AUTOSAR XML (schema 4-0-3)
standard types defined: Boolean, UInt16, UInt32, UInt8
package /AUTOSAR_Platform/DataConstrs
  range DC_Boolean: raw 0..1
  range DC_UInt16: raw 0..65535
  range DC_UInt8: raw 0..255
package /PATAC/MSM/ComponentTypes
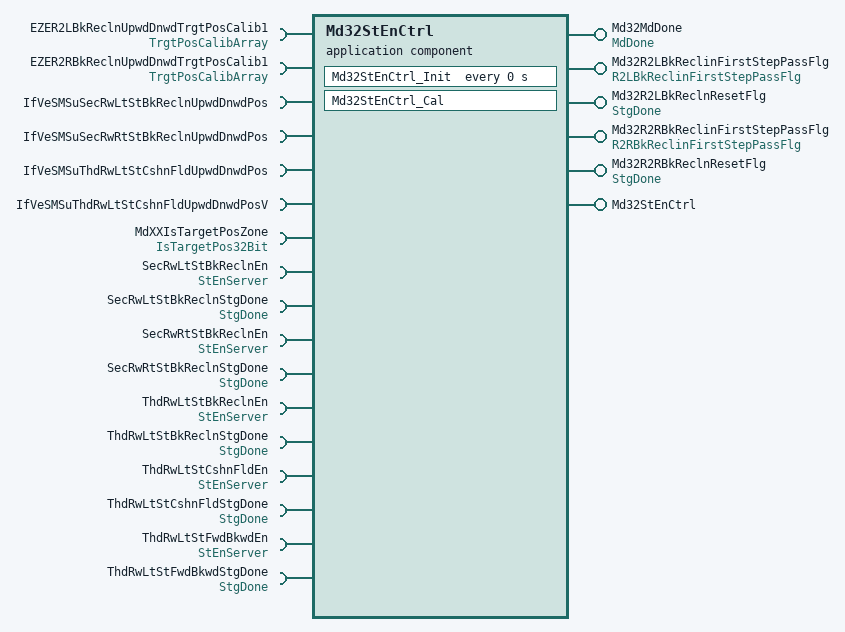
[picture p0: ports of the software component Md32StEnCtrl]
  application sw component type Md32StEnCtrl
    6 x provide port:
      Md32MdDone: nonqueued-sender-com-spec{data-element=MdDone/Val, init-value=0}, provided-interface=MdDone
      Md32R2LBkReclinFirstStepPassFlg: nonqueued-sender-com-spec{data-element=R2LBkReclinFirstStepPassFlg/Val, init-value=0}, provided-interface=R2LBkReclinFirstStepPassFlg
      Md32R2LBkReclnResetFlg: nonqueued-sender-com-spec{data-element=StgDone/Val, init-value=0}, provided-interface=StgDone
      Md32R2RBkReclinFirstStepPassFlg: nonqueued-sender-com-spec{data-element=R2RBkReclinFirstStepPassFlg/Val, init-value=0}, provided-interface=R2RBkReclinFirstStepPassFlg
      Md32R2RBkReclnResetFlg: nonqueued-sender-com-spec{data-element=StgDone/Val, init-value=0}, provided-interface=StgDone
      Md32StEnCtrl: server-com-spec{operation=Cal, queue-length=1}, provided-interface=Md32StEnCtrl
    17 x require port:
      EZER2LBkReclnUpwdDnwdTrgtPosCalib1: nonqueued-receiver-com-spec{data-element=TrgtPosArray, filter=data-filter-type=ALWAYS, init-value=[4095, 4095, 4095]}, required-interface=TrgtPosCalibArray
      EZER2RBkReclnUpwdDnwdTrgtPosCalib1: nonqueued-receiver-com-spec{data-element=TrgtPosArray, filter=data-filter-type=ALWAYS, init-value=[4095, 4095, 4095]}, required-interface=TrgtPosCalibArray
      IfVeSMSuSecRwLtStBkReclnUpwdDnwdPos: nonqueued-receiver-com-spec{data-element=IfVeSMSuSecRwLtStBkReclnUpwdDnwdPos/Val, filter=data-filter-type=ALWAYS, init-value=0}, required-interface=IfVeSMSuSecRwLtStBkReclnUpwdDnwdPos
      IfVeSMSuSecRwRtStBkReclnUpwdDnwdPos: nonqueued-receiver-com-spec{data-element=IfVeSMSuSecRwRtStBkReclnUpwdDnwdPos/Val, filter=data-filter-type=ALWAYS, init-value=0}, required-interface=IfVeSMSuSecRwRtStBkReclnUpwdDnwdPos
      IfVeSMSuThdRwLtStCshnFldUpwdDnwdPos: nonqueued-receiver-com-spec{data-element=IfVeSMSuThdRwLtStCshnFldUpwdDnwdPos/Val, filter=data-filter-type=ALWAYS, init-value=0}, required-interface=IfVeSMSuThdRwLtStCshnFldUpwdDnwdPos
      IfVeSMSuThdRwLtStCshnFldUpwdDnwdPosV: nonqueued-receiver-com-spec{data-element=IfVeSMSuThdRwLtStCshnFldUpwdDnwdPosV/Val, filter=data-filter-type=ALWAYS, init-value=0}, required-interface=IfVeSMSuThdRwLtStCshnFldUpwdDnwdPosV
      MdXXIsTargetPosZone: nonqueued-receiver-com-spec{data-element=IsTargetPos32Bit/Val, filter=data-filter-type=ALWAYS, init-value=0}, required-interface=IsTargetPos32Bit
      SecRwLtStBkReclnEn: required-com-specs=[Clear, Get, Set], required-interface=StEnServer
      SecRwLtStBkReclnStgDone: nonqueued-receiver-com-spec{data-element=StgDone/Val, filter=data-filter-type=ALWAYS, init-value=0}, required-interface=StgDone
      SecRwRtStBkReclnEn: required-com-specs=[Clear, Get, Set], required-interface=StEnServer
      SecRwRtStBkReclnStgDone: nonqueued-receiver-com-spec{data-element=StgDone/Val, filter=data-filter-type=ALWAYS, init-value=0}, required-interface=StgDone
      ThdRwLtStBkReclnEn: required-com-specs=[Clear, Get, Set], required-interface=StEnServer
      ThdRwLtStBkReclnStgDone: nonqueued-receiver-com-spec{data-element=StgDone/Val, filter=data-filter-type=ALWAYS, init-value=0}, required-interface=StgDone
      ThdRwLtStCshnFldEn: required-com-specs=[Clear, Get, Set], required-interface=StEnServer
      ThdRwLtStCshnFldStgDone: nonqueued-receiver-com-spec{data-element=StgDone/Val, filter=data-filter-type=ALWAYS, init-value=0}, required-interface=StgDone
      ThdRwLtStFwdBkwdEn: required-com-specs=[Clear, Get, Set], required-interface=StEnServer
      ThdRwLtStFwdBkwdStgDone: nonqueued-receiver-com-spec{data-element=StgDone/Val, filter=data-filter-type=ALWAYS, init-value=0}, required-interface=StgDone
    behavior Md32StEnCtrl_InternalBehavior
      operation invoked event OIT_Md32StEnCtrl_Cal_Md32StEnCtrl_Cal: start-on-event=Md32StEnCtrl_Cal, operation=Md32StEnCtrl.Cal
      timing event Md32StEnCtrl_InitEvent: start-on-event=Md32StEnCtrl_Init, period=0
      runnable Md32StEnCtrl_Cal
        data-receive-point-by-arguments:
          12 x access:
            REC_EZER2LBkReclnUpwdDnwdTrgtPosCalib1_TrgtPosArray: accessed-variable=EZER2LBkReclnUpwdDnwdTrgtPosCalib1.TrgtPosArray
            REC_EZER2RBkReclnUpwdDnwdTrgtPosCalib1_TrgtPosArray: accessed-variable=EZER2RBkReclnUpwdDnwdTrgtPosCalib1.TrgtPosArray
            REC_IfVeSMSuSecRwLtStBkReclnUpwdDnwdPos_Val: accessed-variable=IfVeSMSuSecRwLtStBkReclnUpwdDnwdPos.Val
            REC_IfVeSMSuSecRwRtStBkReclnUpwdDnwdPos_Val: accessed-variable=IfVeSMSuSecRwRtStBkReclnUpwdDnwdPos.Val
            REC_IfVeSMSuThdRwLtStCshnFldUpwdDnwdPos_Val: accessed-variable=IfVeSMSuThdRwLtStCshnFldUpwdDnwdPos.Val
            REC_IfVeSMSuThdRwLtStCshnFldUpwdDnwdPosV_Val: accessed-variable=IfVeSMSuThdRwLtStCshnFldUpwdDnwdPosV.Val
            REC_MdXXIsTargetPosZone_Val: accessed-variable=MdXXIsTargetPosZone.Val
            REC_SecRwLtStBkReclnStgDone_Val: accessed-variable=SecRwLtStBkReclnStgDone.Val
            REC_SecRwRtStBkReclnStgDone_Val: accessed-variable=SecRwRtStBkReclnStgDone.Val
            REC_ThdRwLtStBkReclnStgDone_Val: accessed-variable=ThdRwLtStBkReclnStgDone.Val
            REC_ThdRwLtStCshnFldStgDone_Val: accessed-variable=ThdRwLtStCshnFldStgDone.Val
            REC_ThdRwLtStFwdBkwdStgDone_Val: accessed-variable=ThdRwLtStFwdBkwdStgDone.Val
        data-send-points:
          5 x access:
            SEND_Md32MdDone_Val: accessed-variable=Md32MdDone.Val
            SEND_Md32R2BkReclnResetFlg_Val: accessed-variable=Md32R2LBkReclnResetFlg.Val
            SEND_Md32R2RBkReclnResetFlg_Val: accessed-variable=Md32R2RBkReclnResetFlg.Val
            SEND_R2LBkReclinFirstStepPassFlg_Val: accessed-variable=Md32R2LBkReclinFirstStepPassFlg.Val
            SEND_R2RBkReclinFirstStepPassFlg_Val: accessed-variable=Md32R2RBkReclinFirstStepPassFlg.Val
        10 x sync call, all with timeout=0:
          SC_SecRwLtStBkReclnEn_Clear: operation=SecRwLtStBkReclnEn.Clear
          SC_SecRwLtStBkReclnEn_Set: operation=SecRwLtStBkReclnEn.Set
          SC_SecRwRtStBkReclnEn_Clear: operation=SecRwRtStBkReclnEn.Clear
          SC_SecRwRtStBkReclnEn_Set: operation=SecRwRtStBkReclnEn.Set
          SC_ThdRwLtStBkReclnEn_Clear: operation=ThdRwLtStBkReclnEn.Clear
          SC_ThdRwLtStBkReclnEn_Set: operation=ThdRwLtStBkReclnEn.Set
          SC_ThdRwLtStCshnFldEn_Clear: operation=ThdRwLtStCshnFldEn.Clear
          SC_ThdRwLtStCshnFldEn_Set: operation=ThdRwLtStCshnFldEn.Set
          SC_ThdRwLtStFwdBkwdEn_Clear: operation=ThdRwLtStFwdBkwdEn.Clear
          SC_ThdRwLtStFwdBkwdEn_Set: operation=ThdRwLtStFwdBkwdEn.Set
      runnable Md32StEnCtrl_Init
  swc implementation Md32StEnCtrl_Implementation: behavior=Md32StEnCtrl_InternalBehavior
    code-descriptors:
      code Default: artifact-descriptors=autosar-engineering-object={short-label=Default, category=SWSRC}
package /PATAC/MSM/ModeAdjust/DataType
  impl type TrgtPosCalibArray: category=ARRAY, sw-calibration-access=READ-ONLY, type-emitter=RTE  # 0:pos 1:max 2:min
    element Element: array-size=3, array-size-semantics=FIXED-SIZE, implementation-data-type=UInt16, invalid-value=0
package /PATAC/MSM/ModeAdjust/Interfaces
  sender receiver interface IfVeSMSuThdRwLtStCshnFldUpwdDnwdPos: invalidation-policy{data-element=IfVeSMSuThdRwLtStCshnFldUpwdDnwdPos/Val, handle-invalid=DONT-INVALIDATE}
    data Val: type=UInt16
  sender receiver interface IfVeSMSuThdRwLtStCshnFldUpwdDnwdPosV: invalidation-policy{data-element=IfVeSMSuThdRwLtStCshnFldUpwdDnwdPosV/Val, handle-invalid=DONT-INVALIDATE}
    data Val: type=Boolean
package /PATAC/MSM/ModeAdjust/PortInterface
  client server interface Md32StEnCtrl
    operation Cal
      arg FirstTrig: type=Boolean, direction=IN, server-argument-impl-policy=USE-ARGUMENT-TYPE
  client server interface StEnServer
    operation Clear
      arg data: type=UInt8, direction=IN, server-argument-impl-policy=USE-ARGUMENT-TYPE
    operation Get
      arg data: type=UInt32, direction=OUT, server-argument-impl-policy=USE-ARGUMENT-TYPE
    operation Set
      arg data: type=UInt8, direction=IN, server-argument-impl-policy=USE-ARGUMENT-TYPE
  6 x sender receiver interface:
    IsTargetPos32Bit: invalidation-policy{data-element=IsTargetPos32Bit/Val, handle-invalid=DONT-INVALIDATE}
      data Val: type=UInt32
    MdDone: invalidation-policy{data-element=MdDone/Val, handle-invalid=DONT-INVALIDATE}
      data Val: type=UInt8
    R2LBkReclinFirstStepPassFlg: invalidation-policy{data-element=R2LBkReclinFirstStepPassFlg/Val, handle-invalid=DONT-INVALIDATE}
      data Val: type=Boolean
    R2RBkReclinFirstStepPassFlg: invalidation-policy{data-element=R2RBkReclinFirstStepPassFlg/Val, handle-invalid=DONT-INVALIDATE}
      data Val: type=Boolean
    StgDone: invalidation-policy{data-element=StgDone/Val, handle-invalid=DONT-INVALIDATE}
      data Val: type=Boolean
    TrgtPosCalibArray: invalidation-policy{data-element=TrgtPosArray, handle-invalid=DONT-INVALIDATE}
      data TrgtPosArray: type=TrgtPosCalibArray  # 0:Pos 1:Max 2:Min
package /PATAC/MSM/PortInterfaces
  sender receiver interface IfVeSMSuSecRwLtStBkReclnUpwdDnwdPos: invalidation-policy{data-element=IfVeSMSuSecRwLtStBkReclnUpwdDnwdPos/Val, handle-invalid=DONT-INVALIDATE}
    data Val: type=UInt16
  sender receiver interface IfVeSMSuSecRwRtStBkReclnUpwdDnwdPos: invalidation-policy{data-element=IfVeSMSuSecRwRtStBkReclnUpwdDnwdPos/Val, handle-invalid=DONT-INVALIDATE}
    data Val: type=UInt16
